AUTOSAR XML (schema 4-3-0)
package /Comp_MCU_ARPkg
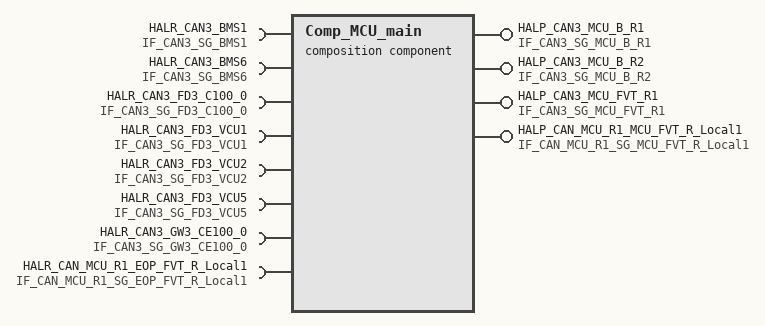
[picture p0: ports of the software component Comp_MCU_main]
  composition sw component type Comp_MCU_main
    8 x require port:
      HALR_CAN3_BMS1: nonqueued-receiver-com-spec{data-element=CAN3_SG_BMS1, handle-out-of-range=DEFAULT, enable-update=true, init-value=constant-reference=Init_CAN3_SG_BMS1}, required-interface=IF_CAN3_SG_BMS1
      HALR_CAN3_BMS6: nonqueued-receiver-com-spec{data-element=CAN3_SG_BMS6, handle-out-of-range=DEFAULT, enable-update=true, init-value=constant-reference=Init_CAN3_SG_BMS6}, required-interface=IF_CAN3_SG_BMS6
      HALR_CAN3_FD3_C100_0: nonqueued-receiver-com-spec{data-element=CAN3_SG_FD3_C100_0, handle-out-of-range=DEFAULT, enable-update=true, init-value=constant-reference=Init_CAN3_SG_FD3_C100_0}, required-interface=IF_CAN3_SG_FD3_C100_0
      HALR_CAN3_FD3_VCU1: nonqueued-receiver-com-spec{data-element=CAN3_SG_FD3_VCU1, handle-out-of-range=DEFAULT, enable-update=true, init-value=constant-reference=Init_CAN3_SG_FD3_VCU1}, required-interface=IF_CAN3_SG_FD3_VCU1
      HALR_CAN3_FD3_VCU2: nonqueued-receiver-com-spec{data-element=CAN3_SG_FD3_VCU2, handle-out-of-range=DEFAULT, enable-update=true, init-value=constant-reference=Init_CAN3_SG_FD3_VCU2}, required-interface=IF_CAN3_SG_FD3_VCU2
      HALR_CAN3_FD3_VCU5: nonqueued-receiver-com-spec{data-element=CAN3_SG_FD3_VCU5, handle-out-of-range=DEFAULT, enable-update=true, init-value=constant-reference=Init_CAN3_SG_FD3_VCU5}, required-interface=IF_CAN3_SG_FD3_VCU5
      HALR_CAN3_GW3_CE100_0: nonqueued-receiver-com-spec{data-element=CAN3_SG_GW3_CE100_0, handle-out-of-range=DEFAULT, enable-update=true, init-value=constant-reference=Init_CAN3_SG_GW3_CE100_0}, required-interface=IF_CAN3_SG_GW3_CE100_0
      HALR_CAN_MCU_R1_EOP_FVT_R_Local1: nonqueued-receiver-com-spec{data-element=CAN_MCU_R1_SG_EOP_FVT_R_Local1, handle-out-of-range=DEFAULT, enable-update=true, init-value=constant-reference=Init_CAN_MCU_R1_SG_EOP_FVT_R_Local1}, required-interface=IF_CAN_MCU_R1_SG_EOP_FVT_R_Local1
    4 x provide port:
      HALP_CAN3_MCU_B_R1: nonqueued-sender-com-spec{data-element=CAN3_SG_MCU_B_R1, handle-out-of-range=DEFAULT, init-value=constant-reference=Init_CAN3_SG_MCU_B_R1}, provided-interface=IF_CAN3_SG_MCU_B_R1
      HALP_CAN3_MCU_B_R2: nonqueued-sender-com-spec{data-element=CAN3_SG_MCU_B_R2, handle-out-of-range=DEFAULT, init-value=constant-reference=Init_CAN3_SG_MCU_B_R2}, provided-interface=IF_CAN3_SG_MCU_B_R2
      HALP_CAN3_MCU_FVT_R1: nonqueued-sender-com-spec{data-element=CAN3_SG_MCU_FVT_R1, handle-out-of-range=DEFAULT, init-value=constant-reference=Init_CAN3_SG_MCU_FVT_R1}, provided-interface=IF_CAN3_SG_MCU_FVT_R1
      HALP_CAN_MCU_R1_MCU_FVT_R_Local1: nonqueued-sender-com-spec{data-element=CAN_MCU_R1_SG_MCU_FVT_R_Local1, handle-out-of-range=DEFAULT, init-value=constant-reference=Init_CAN_MCU_R1_SG_MCU_FVT_R_Local1}, provided-interface=IF_CAN_MCU_R1_SG_MCU_FVT_R_Local1
    component SWC_APP: type=SWC_APP_type
    component SWC_ETE: type=SWC_ETE_type
    delegate SWC_APP.R_CAN3_BMS1 <-> outer port HALR_CAN3_BMS1
    delegate SWC_APP.R_CAN3_BMS6 <-> outer port HALR_CAN3_BMS6
    delegate SWC_APP.R_CAN3_FD3_C100_0 <-> outer port HALR_CAN3_FD3_C100_0
    delegate SWC_APP.R_CAN3_FD3_VCU1 <-> outer port HALR_CAN3_FD3_VCU1
    delegate SWC_APP.R_CAN3_FD3_VCU2 <-> outer port HALR_CAN3_FD3_VCU2
    delegate SWC_APP.R_CAN3_FD3_VCU5 <-> outer port HALR_CAN3_FD3_VCU5
    delegate SWC_APP.R_CAN3_GW3_CE100_0 <-> outer port HALR_CAN3_GW3_CE100_0
    delegate SWC_APP.R_CAN_MCU_R1_EOP_FVT_R_Local1 <-> outer port HALR_CAN_MCU_R1_EOP_FVT_R_Local1
    delegate SWC_APP.P_CAN3_MCU_B_R1 <-> outer port HALP_CAN3_MCU_B_R1
    delegate SWC_APP.P_CAN3_MCU_B_R2 <-> outer port HALP_CAN3_MCU_B_R2
    delegate SWC_APP.P_CAN3_MCU_FVT_R1 <-> outer port HALP_CAN3_MCU_FVT_R1
    delegate SWC_APP.P_CAN_MCU_R1_MCU_FVT_R_Local1 <-> outer port HALP_CAN_MCU_R1_MCU_FVT_R_Local1
    connect SWC_APP.P_LoRateTxHiRateRx -> SWC_ETE.R_LoRateTxHiRateRx
    connect SWC_ETE.P_HiRateTxLoRateRx -> SWC_APP.R_HiRateTxLoRateRx
